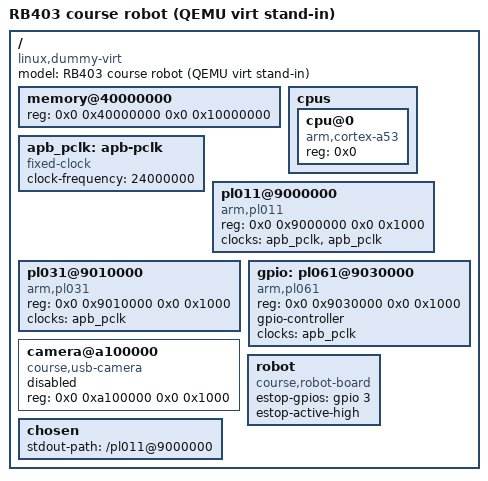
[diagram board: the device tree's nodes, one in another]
// robot.dts - F9-67: the devicetree of the course board's robot image.
// The "course board" in this build is QEMU's Arm virt machine (qemu-system-aarch64 -M virt,acpi=off).
// Addresses below are the ones QEMU 8.2.2 placed on that machine (read from its own generated
// devicetree with the F4-31 tool); on a real board they come from the board's devicetree.
// Compiled with minidtc.py (the course's own subset compiler; the container has no dtc).
/ {
    model = "RB403 course robot (QEMU virt stand-in)";
    compatible = "linux,dummy-virt";
    #address-cells = <2>;
    #size-cells = <2>;

    memory@40000000 {
        device_type = "memory";
        reg = <0x0 0x40000000 0x0 0x10000000>;
    };

    cpus {
        #address-cells = <1>;
        #size-cells = <0>;
        cpu@0 {
            device_type = "cpu";
            compatible = "arm,cortex-a53";
            reg = <0x0>;
        };
    };

    apb_pclk: apb-pclk {
        compatible = "fixed-clock";
        #clock-cells = <0>;
        clock-frequency = <24000000>;
    };

    pl011@9000000 {
        compatible = "arm,pl011", "arm,primecell";
        reg = <0x0 0x9000000 0x0 0x1000>;
        clocks = <&apb_pclk &apb_pclk>;
        clock-names = "uartclk", "apb_pclk";
    };

    pl031@9010000 {
        compatible = "arm,pl031", "arm,primecell";
        reg = <0x0 0x9010000 0x0 0x1000>;
        clocks = <&apb_pclk>;
        clock-names = "apb_pclk";
    };

    gpio: pl061@9030000 {
        compatible = "arm,pl061", "arm,primecell";
        reg = <0x0 0x9030000 0x0 0x1000>;
        gpio-controller;
        #gpio-cells = <2>;
        clocks = <&apb_pclk>;
        clock-names = "apb_pclk";
        status = "okay";
    };

    // A USB camera controller the robot has but this image does not drive yet: present,
    // switched off on purpose, so the binder must skip it.
    camera@a100000 {
        compatible = "course,usb-camera";
        reg = <0x0 0xa100000 0x0 0x1000>;
        status = "disabled";
    };

    // The robot's own wiring: which input is the emergency stop. On QEMU virt the
    // "power button" is wired to line 3 of the PL061 (see QEMU's generated gpio-keys node),
    // and the lab presses it from the QEMU monitor. "course," is this course's own prefix,
    // not a registered vendor prefix.
    robot {
        compatible = "course,robot-board";
        estop-gpios = <&gpio 3 0>;
        estop-active-high;
    };

    chosen {
        stdout-path = "/pl011@9000000";
    };
};
